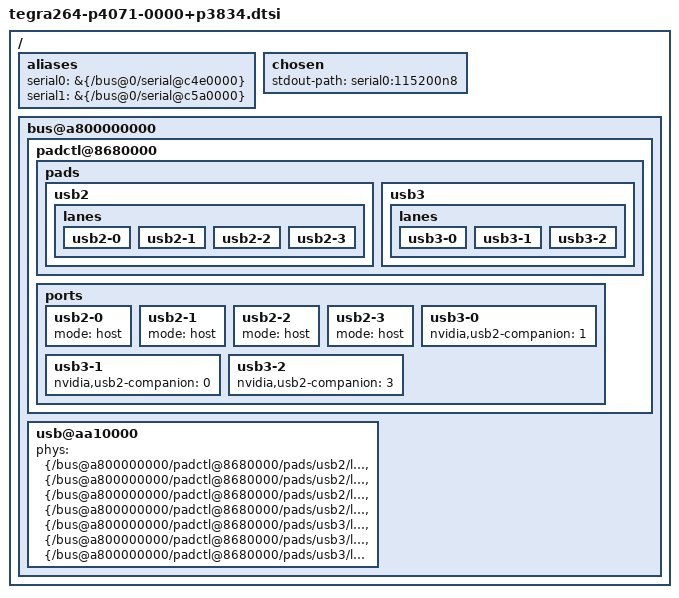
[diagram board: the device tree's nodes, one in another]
// SPDX-License-Identifier: GPL-2.0-only OR BSD-2-Clause

/ {
	aliases {
		serial0 = &{/bus@0/serial@c4e0000};
		serial1 = &{/bus@0/serial@c5a0000};
	};

	chosen {
		stdout-path = "serial0:115200n8";
	};

	bus@a800000000 {
		padctl@8680000 {
			status = "okay";

			pads {
				usb2 {
					lanes {
						usb2-0 {
							status = "okay";
						};

						usb2-1 {
							status = "okay";
						};

						usb2-2 {
							status = "okay";
						};

						usb2-3 {
							status = "okay";
						};
					};
				};

				usb3 {
					lanes {
						usb3-0 {
							status = "okay";
						};

						usb3-1 {
							status = "okay";
						};

						usb3-2 {
							status = "okay";
						};
					};
				};
			};

			ports {
				usb2-0 {
					mode = "host";
					status = "okay";
				};

				usb2-1 {
					mode = "host";
					status = "okay";
				};

				usb2-2 {
					mode = "host";
					status = "okay";
				};

				usb2-3 {
					mode = "host";
					status = "okay";
				};

				usb3-0 {
					nvidia,usb2-companion = <1>;
					status = "okay";
				};

				usb3-1 {
					nvidia,usb2-companion = <0>;
					status = "okay";
				};

				usb3-2 {
					nvidia,usb2-companion = <3>;
					status = "okay";
				};
			};
		};

		usb@aa10000 {
			status = "okay";

			phys = <&{/bus@a800000000/padctl@8680000/pads/usb2/lanes/usb2-0}>,
			       <&{/bus@a800000000/padctl@8680000/pads/usb2/lanes/usb2-1}>,
			       <&{/bus@a800000000/padctl@8680000/pads/usb2/lanes/usb2-2}>,
			       <&{/bus@a800000000/padctl@8680000/pads/usb2/lanes/usb2-3}>,
			       <&{/bus@a800000000/padctl@8680000/pads/usb3/lanes/usb3-0}>,
			       <&{/bus@a800000000/padctl@8680000/pads/usb3/lanes/usb3-1}>,
			       <&{/bus@a800000000/padctl@8680000/pads/usb3/lanes/usb3-2}>;
			phy-names = "usb2-0", "usb2-1", "usb2-2", "usb2-3",
				    "usb3-0", "usb3-1", "usb3-2";
		};
	};
};
